# STM32L4S7 register map
File version: 2.2
CPU: CM4 r0p1, little endian, MPU, FPU, 4 interrupt priority bits
Registers are 32-bit, read-write, reset 0x0 unless marked. A register's access mark holds for its fields unless they carry their own. Offsets are from the block's base; [hi:lo] are bit positions; 'fields as' and 'values as' point back to an identical list.

## LTCD — Liquid crystal display controller
Base 0x40016800
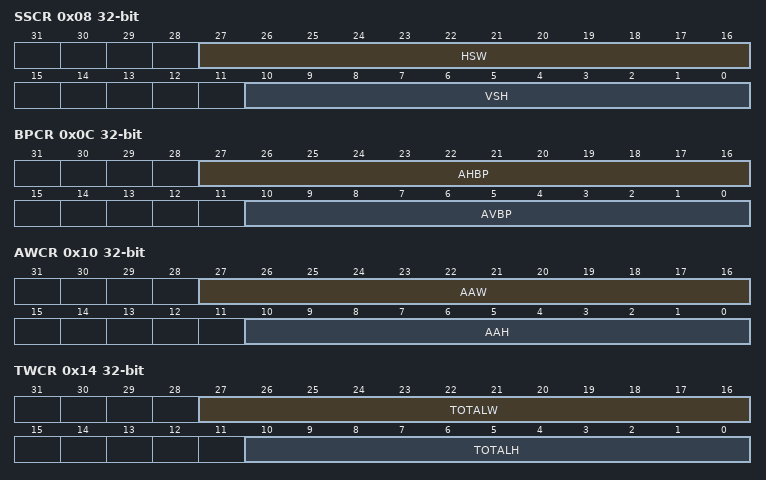
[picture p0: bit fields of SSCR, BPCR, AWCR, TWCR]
0x08 SSCR — LTDC Synchronization Size Configuration Register
  [27:16] HSW — Horizontal Synchronization Width (in units of pixel clock period)
  [10:0] VSH — Vertical Synchronization Height (in units of horizontal scan line)
0x0C BPCR — LTDC Back Porch Configuration Register
  [27:16] AHBP — Accumulated Horizontal back porch (in units of pixel clock period)
  [10:0] AVBP — Accumulated Vertical back porch (in units of horizontal scan line)
0x10 AWCR — LTDC Active Width Configuration Register
  [27:16] AAW — Accumulated Active Width (in units of pixel clock period)
  [10:0] AAH — Accumulated Active Height (in units of horizontal scan line)
0x14 TWCR — LTDC Total Width Configuration Register
  [27:16] TOTALW — Total Width (in units of pixel clock period)
  [10:0] TOTALH — Total Height (in units of horizontal scan line)
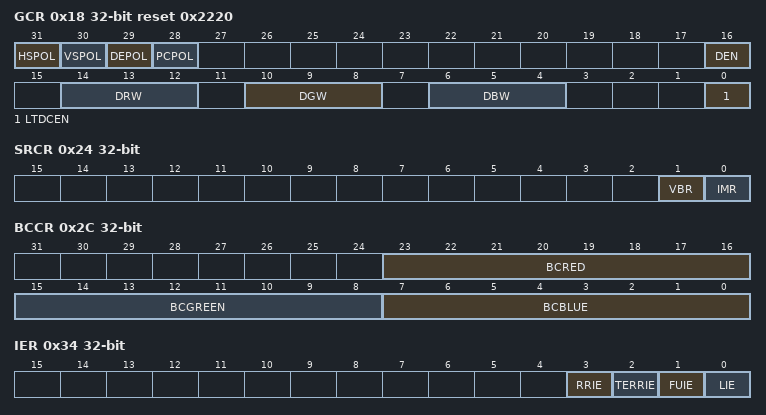
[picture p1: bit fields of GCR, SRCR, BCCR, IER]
0x18 GCR access per field reset 0x2220 — LTDC Global Control Register
  [31] HSPOL rw — Horizontal Synchronization Polarity
  [30] VSPOL rw — Vertical Synchronization Polarity
  [29] DEPOL rw — Not Data Enable Polarity
  [28] PCPOL rw — Pixel Clock Polarity
  [16] DEN rw — Dither Enable
  [14:12] DRW ro — Dither Red Width
  [10:8] DGW ro — Dither Green Width
  [6:4] DBW ro — Dither Blue Width
  [0] LTDCEN rw — LCD-TFT controller enable bit
0x24 SRCR — LTDC Shadow Reload Configuration Register
  [1] VBR — Vertical Blanking Reload
  [0] IMR — Immediate Reload
0x2C BCCR — LTDC Background Color Configuration Register
  [23:16] BCRED — Background Color Red value
  [15:8] BCGREEN — Background Color Green value
  [7:0] BCBLUE — Background Color Blue value
0x34 IER — LTDC Interrupt Enable Register
  [3] RRIE — Register Reload interrupt enable
  [2] TERRIE — Transfer Error Interrupt Enable
  [1] FUIE — FIFO Underrun Interrupt Enable
  [0] LIE — Line Interrupt Enable
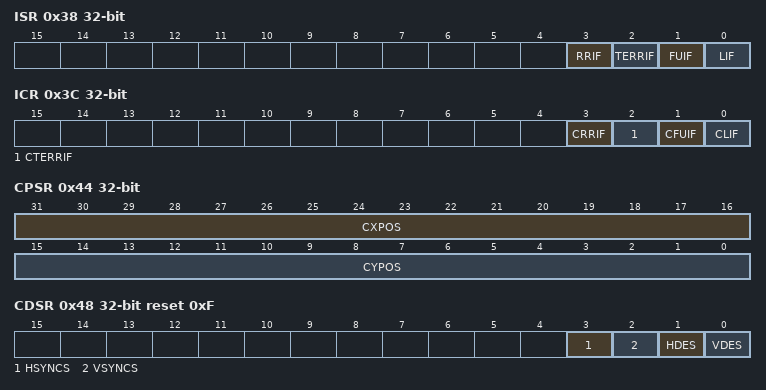
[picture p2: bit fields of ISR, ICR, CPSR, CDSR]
0x38 ISR ro — LTDC Interrupt Status Register
  [3] RRIF — Register Reload Interrupt Flag
  [2] TERRIF — Transfer Error interrupt flag
  [1] FUIF — FIFO Underrun Interrupt flag
  [0] LIF — Line Interrupt flag
0x3C ICR wo — LTDC Interrupt Clear Register
  [3] CRRIF — Clears Register Reload Interrupt Flag
  [2] CTERRIF — Clears the Transfer Error Interrupt Flag
  [1] CFUIF — Clears the FIFO Underrun Interrupt flag
  [0] CLIF — Clears the Line Interrupt Flag
0x40 LIPCR — LTDC Line Interrupt Position Configuration Register
  [10:0] LIPOS — Line Interrupt Position
0x44 CPSR ro — LTDC Current Position Status Register
  [31:16] CXPOS — Current X Position
  [15:0] CYPOS — Current Y Position
0x48 CDSR ro reset 0xF — LTDC Current Display Status Register
  [3] HSYNCS — Horizontal Synchronization display Status
  [2] VSYNCS — Vertical Synchronization display Status
  [1] HDES — Horizontal Data Enable display Status
  [0] VDES — Vertical Data Enable display Status
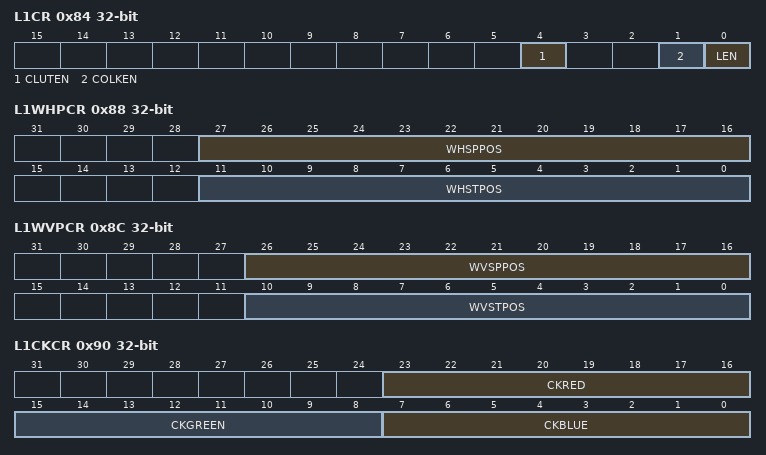
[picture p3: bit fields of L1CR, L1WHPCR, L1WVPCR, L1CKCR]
0x84 L1CR — LTDC Layer Control Register
  [4] CLUTEN — Color Look-Up Table Enable
  [1] COLKEN — Color Keying Enable
  [0] LEN — Layer Enable
0x88 L1WHPCR — LTDC Layer Window Horizontal Position Configuration Register
  [27:16] WHSPPOS — Window Horizontal Stop Position
  [11:0] WHSTPOS — Window Horizontal Start Position
0x8C L1WVPCR — LTDC Layer Window Vertical Position Configuration Register
  [26:16] WVSPPOS — Window Vertical Stop Position
  [10:0] WVSTPOS — Window Vertical Start Position
0x90 L1CKCR — LTDC Layer Color Keying Configuration Register
  [23:16] CKRED — Color Key Red value
  [15:8] CKGREEN — Color Key Green value
  [7:0] CKBLUE — Color Key Blue value
0x94 L1PFCR — LTDC Layer Pixel Format Configuration Register
  [2:0] PF — Pixel Format
0x98 L1CACR — LTDC Layer Constant Alpha Configuration Register
  [7:0] CONSTA — Constant Alpha
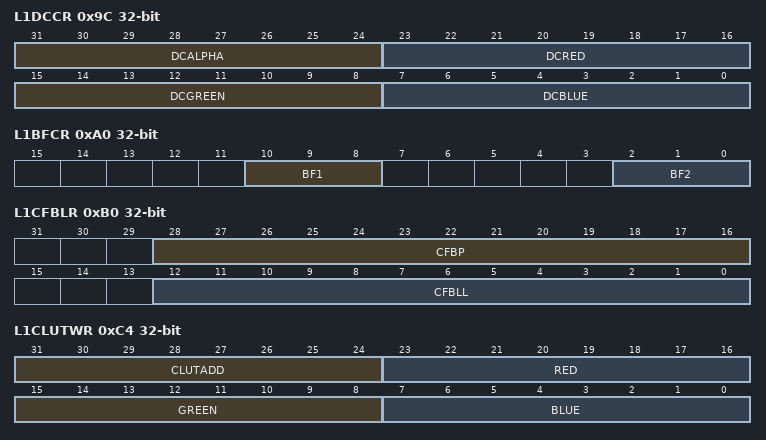
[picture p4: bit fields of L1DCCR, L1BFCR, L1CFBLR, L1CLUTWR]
0x9C L1DCCR — LTDC Layer Default Color Configuration Register
  [31:24] DCALPHA — Default Color Alpha
  [23:16] DCRED — Default Color Red
  [15:8] DCGREEN — Default Color Green
  [7:0] DCBLUE — Default Color Blue
0xA0 L1BFCR — LTDC Layer Blending Factors Configuration Register
  [10:8] BF1 — Blending Factor 1
  [2:0] BF2 — Blending Factor 2
0xAC L1CFBAR — LTDC Layer Color Frame Buffer Address Register
  [31:0] CFBADD — Color Frame Buffer Start Address
0xB0 L1CFBLR — LTDC Layer Color Frame Buffer Length Register
  [28:16] CFBP — Color Frame Buffer Pitch in bytes
  [12:0] CFBLL — Color Frame Buffer Line Length
0xB4 L1CFBLNR — LTDC Layer ColorFrame Buffer Line Number Register
  [10:0] CFBLNBR — Frame Buffer Line Number
0xC4 L1CLUTWR wo — LTDC Layerx CLUT Write Register
  [31:24] CLUTADD — CLUT Address
  [23:16] RED — Red value
  [15:8] GREEN — Green value
  [7:0] BLUE — Blue value
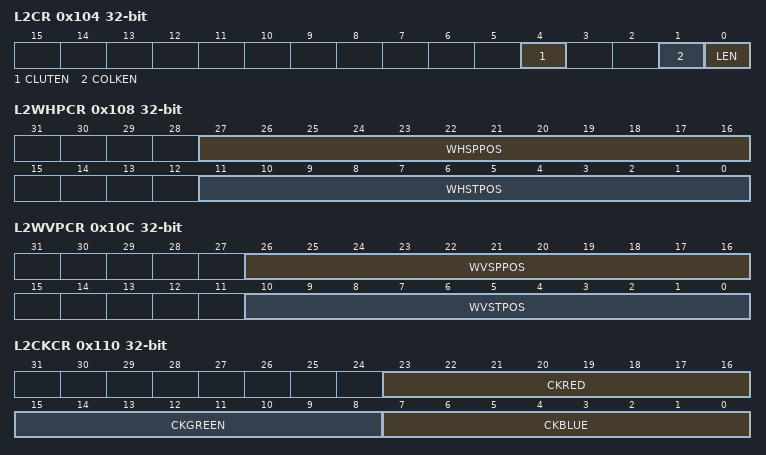
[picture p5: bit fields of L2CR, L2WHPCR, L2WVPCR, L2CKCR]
0x104 L2CR — LTDC Layer Control Register
  fields as L1CR
0x108 L2WHPCR — LTDC Layerx Window Horizontal Position Configuration Register
  fields as L1WHPCR
0x10C L2WVPCR — LTDC Layer Window Vertical Position Configuration Register
  fields as L1WVPCR
0x110 L2CKCR — LTDC Layer Color Keying Configuration Register
  fields as L1CKCR
0x114 L2PFCR — LTDC Layer Pixel Format Configuration Register
  [2:0] PF — Pixel Format
0x118 L2CACR — LTDC Layer Constant Alpha Configuration Register
  [7:0] CONSTA — Constant Alpha
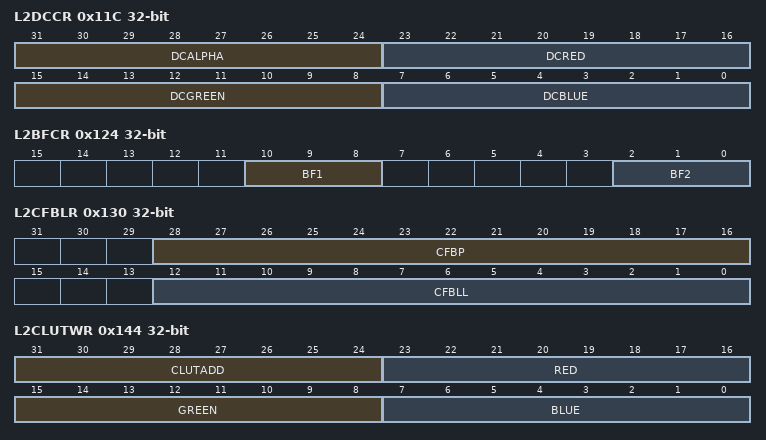
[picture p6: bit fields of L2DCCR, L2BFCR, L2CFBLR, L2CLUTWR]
0x11C L2DCCR — LTDC Layer Default Color Configuration Register
  fields as L1DCCR
0x124 L2BFCR — LTDC Layer Blending Factors Configuration Register
  [10:8] BF1 — Blending Factor 1
  [2:0] BF2 — Blending Factor 2
0x12C L2CFBAR — LTDC Layer Color Frame Buffer Address Register
  [31:0] CFBADD — Color Frame Buffer Start Address
0x130 L2CFBLR — LTDC Layer Color Frame Buffer Length Register
  fields as L1CFBLR
0x134 L2CFBLNR — LTDC Layer ColorFrame Buffer Line Number Register
  [10:0] CFBLNBR — Frame Buffer Line Number
0x144 L2CLUTWR wo — LTDC Layerx CLUT Write Register
  fields as L1CLUTWR

## Notices in the file
Copyright (c) 2025 STMicroelectronics.
SPDX-License-Identifier: Apache-2.0
Licensed under the Apache License, Version 2.0 (the "License");
you may not use this file except in compliance with the License.
You may obtain a copy of the License at
http://www.apache.org/licenses/LICENSE-2.0
Unless required by applicable law or agreed to in writing, software
distributed under the License is distributed on an "AS IS" BASIS,
WITHOUT WARRANTIES OR CONDITIONS OF ANY KIND, either express or implied.
See the License for the specific language governing permissions and
limitations under the License.
